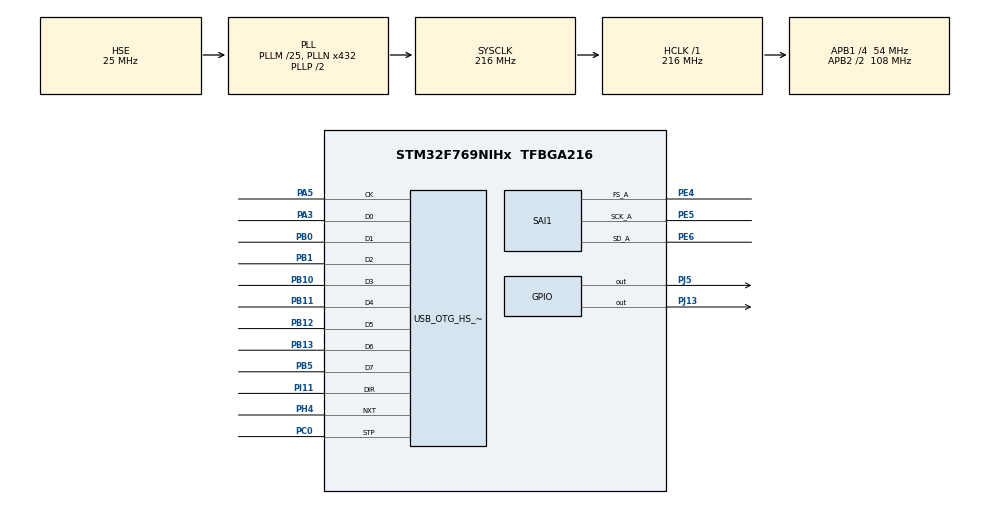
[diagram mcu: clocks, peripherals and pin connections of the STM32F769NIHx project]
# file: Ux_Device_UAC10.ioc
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CORTEX_M7.AccessPermission-Cortex_Memory_Protection_Unit_Region0_Settings=MPU_REGION_NO_ACCESS
CORTEX_M7.AccessPermission-Cortex_Memory_Protection_Unit_Region1_Settings=MPU_REGION_FULL_ACCESS
CORTEX_M7.BaseAddress-Cortex_Memory_Protection_Unit_Region0_Settings=0
CORTEX_M7.BaseAddress-Cortex_Memory_Protection_Unit_Region1_Settings=0x20027000
CORTEX_M7.CPU_DCache=Enabled
CORTEX_M7.CPU_ICache=Enabled
CORTEX_M7.DisableExec-Cortex_Memory_Protection_Unit_Region0_Settings=MPU_INSTRUCTION_ACCESS_DISABLE
CORTEX_M7.DisableExec-Cortex_Memory_Protection_Unit_Region1_Settings=MPU_INSTRUCTION_ACCESS_DISABLE
CORTEX_M7.Enable-Cortex_Memory_Protection_Unit_Region0_Settings=MPU_REGION_ENABLE
CORTEX_M7.Enable-Cortex_Memory_Protection_Unit_Region1_Settings=MPU_REGION_ENABLE
CORTEX_M7.IsShareable-Cortex_Memory_Protection_Unit_Region0_Settings=MPU_ACCESS_SHAREABLE
CORTEX_M7.MPU_Control=MPU_HFNMI_PRIVDEF
CORTEX_M7.Size-Cortex_Memory_Protection_Unit_Region0_Settings=MPU_REGION_SIZE_4GB
CORTEX_M7.Size-Cortex_Memory_Protection_Unit_Region1_Settings=MPU_REGION_SIZE_128KB
CORTEX_M7.SubRegionDisable-Cortex_Memory_Protection_Unit_Region0_Settings=0x87
CORTEX_M7.TypeExtField-Cortex_Memory_Protection_Unit_Region0_Settings=MPU_TEX_LEVEL0
CORTEX_M7.TypeExtField-Cortex_Memory_Protection_Unit_Region1_Settings=MPU_TEX_LEVEL1
Mcu.Family=STM32F7
Mcu.Name=STM32F769NIHx
Mcu.Package=TFBGA216
NVIC.OTG_HS_IRQn=true\:7\:0\:true\:false\:true\:true\:true\:true
NVIC.PriorityGroup=NVIC_PRIORITYGROUP_4
PA10.Signal=USART1_RX
PA3.Mode=Device_HS
PA3.Signal=USB_OTG_HS_ULPI_D0
PA5.Mode=Device_HS
PA5.Signal=USB_OTG_HS_ULPI_CK
PA9.Signal=USART1_TX
PB0.Mode=Device_HS
PB0.Signal=USB_OTG_HS_ULPI_D1
PB1.Mode=Device_HS
PB1.Signal=USB_OTG_HS_ULPI_D2
PB10.Mode=Device_HS
PB10.Signal=USB_OTG_HS_ULPI_D3
PB11.Mode=Device_HS
PB11.Signal=USB_OTG_HS_ULPI_D4
PB12.Mode=Device_HS
PB12.Signal=USB_OTG_HS_ULPI_D5
PB13.Mode=Device_HS
PB13.Signal=USB_OTG_HS_ULPI_D6
PB5.Mode=Device_HS
PB5.Signal=USB_OTG_HS_ULPI_D7
PC0.Mode=Device_HS
PC0.Signal=USB_OTG_HS_ULPI_STP
PE4.Mode=SAI_A_Master
PE4.Signal=SAI1_FS_A
PE5.Mode=SAI_A_Master
PE5.Signal=SAI1_SCK_A
PE6.Mode=SAI_A_Master
PE6.Signal=SAI1_SD_A
PH0/OSC_IN.Mode=HSE-External-Oscillator
PH0/OSC_IN.Signal=RCC_OSC_IN
PH1/OSC_OUT.Mode=HSE-External-Oscillator
PH1/OSC_OUT.Signal=RCC_OSC_OUT
PH4.Mode=Device_HS
PH4.Signal=USB_OTG_HS_ULPI_NXT
PI11.Mode=Device_HS
PI11.Signal=USB_OTG_HS_ULPI_DIR
PJ13.GPIO_PuPd=GPIO_PULLUP
PJ13.GPIO_Speed=GPIO_SPEED_FREQ_HIGH
PJ13.Signal=GPIO_Output
PJ5.GPIO_ModeDefaultOutputPP=GPIO_MODE_OUTPUT_PP
PJ5.GPIO_PuPd=GPIO_PULLUP
PJ5.GPIO_Speed=GPIO_SPEED_FREQ_HIGH
PJ5.Signal=GPIO_Output
ProjectManager.HeapSize=0x200
ProjectManager.StackSize=0x400
ProjectManager.TargetToolchain=EWARM V8.50
RCC.AHBFreq_Value=216000000
RCC.APB1CLKDivider=RCC_HCLK_DIV4
RCC.APB1Freq_Value=54000000
RCC.APB1TimFreq_Value=216000000
RCC.APB2CLKDivider=RCC_HCLK_DIV2
RCC.APB2Freq_Value=108000000
RCC.APB2TimFreq_Value=216000000
RCC.CortexFreq_Value=216000000
RCC.HCLKFreq_Value=216000000
RCC.HSE_VALUE=25000000
RCC.HSI_VALUE=16000000
RCC.LSE_VALUE=32768
RCC.PLLM=25
RCC.PLLN=432
RCC.PLLSAIQ=3
RCC.PLLSourceVirtual=RCC_PLLSOURCE_HSE
RCC.RCC_TIM_PRescaler_Selection=RCC_TIMPRES_ACTIVATED
RCC.SYSCLKFreq_VALUE=216000000
RCC.SYSCLKSource=RCC_SYSCLKSOURCE_PLLCLK
RCC.USBFreq_Value=216000000
RCC.VCOOutputFreq_Value=432000000
SAI1.ErrorAudioFreq-SAI_A_Master=30.2 %
SAI1.Instance-SAI_A_Master=SAI$Index_Block_A
SAI1.MClockEnable-SAI_A_Master=SAI_MASTERCLOCK_DISABLE
SAI1.RealAudioFreq-SAI_A_Master=250.0 KHz
SAI1.VirtualMode-SAI_A_Master=VM_MASTER
STMicroelectronics.X-CUBE-AZRTOS-H7.4.0.0.USBD_PID=0x5408
STMicroelectronics.X-CUBE-AZRTOS-H7.4.0.0.USBD_PRODUCT_STRING=STM32 UAC 1.0
STMicroelectronics.X-CUBE-AZRTOS-H7.4.0.0.USBD_SERIAL_NUMBER=UAC10_SPEAKER001
STMicroelectronics.X-CUBE-AZRTOS-H7.4.0.0.USBD_VID=0x0483
STMicroelectronics.X-CUBE-AZRTOS-H7.4.0.0.USBXCcUSBJjUSBXJjCoreSystem=true
STMicroelectronics.X-CUBE-AZRTOS-H7.4.0.0.USBXCcUSBJjUSBXJjUXOoDeviceOoClassOoAUDIOOoCore=true
STMicroelectronics.X-CUBE-AZRTOS-H7.4.0.0.USBXCcUSBJjUSBXJjUXOoDeviceOoClassOoAUDIOOoRecording=true
STMicroelectronics.X-CUBE-AZRTOS-H7.4.0.0.USBXCcUSBJjUSBXJjUXOoDeviceOoControllers=true
STMicroelectronics.X-CUBE-AZRTOS-H7.4.0.0.USBXCcUSBJjUSBXJjUXOoDeviceOoCoreStack=true
STMicroelectronics.X-CUBE-AZRTOS-H7.4.0.0.USBX_DEVICE_SYS_SIZE=15*1024
STMicroelectronics.X-CUBE-AZRTOS-H7.4.0.0.UX_DEVICE_APP_MEM_POOL_SIZE_STANDLONE=20*1024
STMicroelectronics.X-CUBE-AZRTOS-H7.4.0.0.UX_SLAVE_REQUEST_DATA_MAX_LENGTH=512
STMicroelectronics.X-CUBE-AZRTOS-H7.4.0.0_IsAnAzureRtosMw=true
USB_OTG_HS.DeviceSpeed-Device_HS=PCD_SPEED_FULL
USB_OTG_HS.VirtualMode-Device_HS=Device_HS
USB_OTG_HS.dma_enable-Device_HS=DISABLE
VP_DFSDM1_VS_IN0.Mode=Parallel_Input_ch0
VP_STMicroelectronics.X-CUBE-AZRTOS-H7_VS_USBJjUSBX_6.4.0_4.0.0.Mode=USBJjUSBX
board=custom

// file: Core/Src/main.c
/* USER CODE BEGIN Header */
/**
  ******************************************************************************
  * @file           : main.c
  * @brief          : Main program body
  ******************************************************************************
  * @attention
  *
  * Copyright (c) 2025 STMicroelectronics.
  * All rights reserved.
  *
  * This software is licensed under terms that can be found in the LICENSE file
  * in the root directory of this software component.
  * If no LICENSE file comes with this software, it is provided AS-IS.
  *
  ******************************************************************************
  */
/* USER CODE END Header */
#include "main.h"
#include "gpio.h"

void SystemClock_Config(void);
void PeriphCommonClock_Config(void);
static void MPU_Config(void);

int main(void)
{

  /* MPU Configuration--------------------------------------------------------*/
  MPU_Config();

  /* Enable the CPU Cache */

  /* Enable I-Cache---------------------------------------------------------*/
  SCB_EnableICache();

  /* Enable D-Cache---------------------------------------------------------*/
  SCB_EnableDCache();

  /* MCU Configuration--------------------------------------------------------*/

  /* Reset of all peripherals, Initializes the Flash interface and the Systick. */
  HAL_Init();

  /* Configure the system clock */
  SystemClock_Config();

  /* Configure the peripherals common clocks */
  PeriphCommonClock_Config();

  /* Initialize all configured peripherals */
  MX_GPIO_Init();
  /* USER CODE BEGIN 2 */

  /* USER CODE BEGIN 2 */
  MX_USBX_Device_Init();
  /* USER CODE END 2 */

  /* Infinite loop */
  while (1)
  {

    /* USER CODE BEGIN 3 */
    USBX_Device_Process(NULL);
  }
  /* USER CODE END 3 */
}

void SystemClock_Config(void)
{
  RCC_OscInitTypeDef RCC_OscInitStruct = {0};
  RCC_ClkInitTypeDef RCC_ClkInitStruct = {0};

  /** Configure the main internal regulator output voltage
  */
  __HAL_RCC_PWR_CLK_ENABLE();
  __HAL_PWR_VOLTAGESCALING_CONFIG(PWR_REGULATOR_VOLTAGE_SCALE1);

  /** Initializes the RCC Oscillators according to the specified parameters
  * in the RCC_OscInitTypeDef structure.
  */
  RCC_OscInitStruct.OscillatorType = RCC_OSCILLATORTYPE_HSE;
  RCC_OscInitStruct.HSEState = RCC_HSE_ON;
  RCC_OscInitStruct.PLL.PLLState = RCC_PLL_ON;
  RCC_OscInitStruct.PLL.PLLSource = RCC_PLLSOURCE_HSE;
  RCC_OscInitStruct.PLL.PLLM = 25;
  RCC_OscInitStruct.PLL.PLLN = 432;
  RCC_OscInitStruct.PLL.PLLP = RCC_PLLP_DIV2;
  RCC_OscInitStruct.PLL.PLLQ = 2;
  RCC_OscInitStruct.PLL.PLLR = 2;
  if (HAL_RCC_OscConfig(&RCC_OscInitStruct) != HAL_OK)
  {
    Error_Handler();
  }

  /** Activate the Over-Drive mode
  */
  if (HAL_PWREx_EnableOverDrive() != HAL_OK)
  {
    Error_Handler();
  }

  /** Initializes the CPU, AHB and APB buses clocks
  */
  RCC_ClkInitStruct.ClockType = RCC_CLOCKTYPE_HCLK|RCC_CLOCKTYPE_SYSCLK
                              |RCC_CLOCKTYPE_PCLK1|RCC_CLOCKTYPE_PCLK2;
  RCC_ClkInitStruct.SYSCLKSource = RCC_SYSCLKSOURCE_PLLCLK;
  RCC_ClkInitStruct.AHBCLKDivider = RCC_SYSCLK_DIV1;
  RCC_ClkInitStruct.APB1CLKDivider = RCC_HCLK_DIV4;
  RCC_ClkInitStruct.APB2CLKDivider = RCC_HCLK_DIV2;

  if (HAL_RCC_ClockConfig(&RCC_ClkInitStruct, FLASH_LATENCY_7) != HAL_OK)
  {
    Error_Handler();
  }
}

void PeriphCommonClock_Config(void)
{
  RCC_PeriphCLKInitTypeDef PeriphClkInitStruct = {0};

  /** Initializes the peripherals clock
  */
  PeriphClkInitStruct.PeriphClockSelection = RCC_PERIPHCLK_TIM;
  PeriphClkInitStruct.TIMPresSelection = RCC_TIMPRES_ACTIVATED;

  if (HAL_RCCEx_PeriphCLKConfig(&PeriphClkInitStruct) != HAL_OK)
  {
    Error_Handler();
  }
}

 /* MPU Configuration */

void MPU_Config(void)
{
  MPU_Region_InitTypeDef MPU_InitStruct = {0};

  /* Disables the MPU */
  HAL_MPU_Disable();

  /** Initializes and configures the Region and the memory to be protected
  */
  MPU_InitStruct.Enable = MPU_REGION_ENABLE;
  MPU_InitStruct.Number = MPU_REGION_NUMBER0;
  MPU_InitStruct.BaseAddress = 0;
  MPU_InitStruct.Size = MPU_REGION_SIZE_4GB;
  MPU_InitStruct.SubRegionDisable = 0x87;
  MPU_InitStruct.TypeExtField = MPU_TEX_LEVEL0;
  MPU_InitStruct.AccessPermission = MPU_REGION_NO_ACCESS;
  MPU_InitStruct.DisableExec = MPU_INSTRUCTION_ACCESS_DISABLE;
  MPU_InitStruct.IsShareable = MPU_ACCESS_SHAREABLE;
  MPU_InitStruct.IsCacheable = MPU_ACCESS_NOT_CACHEABLE;
  MPU_InitStruct.IsBufferable = MPU_ACCESS_NOT_BUFFERABLE;

  HAL_MPU_ConfigRegion(&MPU_InitStruct);

  /** Initializes and configures the Region and the memory to be protected
  */
  MPU_InitStruct.Number = MPU_REGION_NUMBER1;
  MPU_InitStruct.BaseAddress = 0x20027000;
  MPU_InitStruct.Size = MPU_REGION_SIZE_128KB;
  MPU_InitStruct.SubRegionDisable = 0x0;
  MPU_InitStruct.TypeExtField = MPU_TEX_LEVEL1;
  MPU_InitStruct.AccessPermission = MPU_REGION_FULL_ACCESS;
  MPU_InitStruct.IsShareable = MPU_ACCESS_NOT_SHAREABLE;

  HAL_MPU_ConfigRegion(&MPU_InitStruct);
  /* Enables the MPU */
  HAL_MPU_Enable(MPU_HFNMI_PRIVDEF);

}

void Error_Handler(void)
{
  __disable_irq();
  while (1)
  {
  }
}
